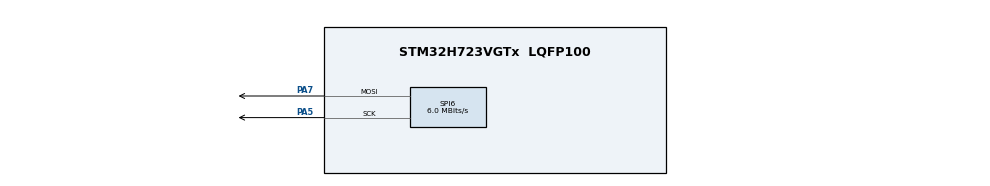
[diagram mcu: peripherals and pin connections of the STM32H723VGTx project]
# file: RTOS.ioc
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CORTEX_M7.default_mode_Activation=1
FREERTOS.Tasks01=defaultTask,0,128,StartDefaultTask,Default,NULL,Dynamic,NULL,NULL;Flash,0,128,StartFlashTask,Default,NULL,Dynamic,NULL,NULL;Breath,0,128,StartBreathTask,Default,NULL,Dynamic,NULL,NULL
Mcu.Family=STM32H7
Mcu.Name=STM32H723VGTx
Mcu.Package=LQFP100
NVIC.PriorityGroup=NVIC_PRIORITYGROUP_4
PA13(JTMS/SWDIO).Mode=Serial_Wire
PA13(JTMS/SWDIO).Signal=DEBUG_JTMS-SWDIO
PA14(JTCK/SWCLK).Mode=Serial_Wire
PA14(JTCK/SWCLK).Signal=DEBUG_JTCK-SWCLK
PA5.Mode=TX_Only_Simplex_Unidirect_Master
PA5.Signal=SPI6_SCK
PA7.Mode=TX_Only_Simplex_Unidirect_Master
PA7.Signal=SPI6_MOSI
PH0-OSC_IN.Mode=HSE-External-Oscillator
PH0-OSC_IN.Signal=RCC_OSC_IN
PH1-OSC_OUT.Mode=HSE-External-Oscillator
PH1-OSC_OUT.Signal=RCC_OSC_OUT
ProjectManager.HeapSize=0x200
ProjectManager.StackSize=0x400
ProjectManager.TargetToolchain=CMake
RCC.ADCFreq_Value=48375000
RCC.APB1Freq_Value=120000000
RCC.APB2Freq_Value=120000000
RCC.APB3Freq_Value=120000000
RCC.APB4Freq_Value=120000000
RCC.CortexFreq_Value=480000000
RCC.D1PPRE=RCC_APB3_DIV2
RCC.D2PPRE1=RCC_APB1_DIV2
RCC.D2PPRE2=RCC_APB2_DIV2
RCC.D3PPRE=RCC_APB4_DIV2
RCC.DIVM1=2
RCC.DIVN1=40
RCC.DIVP1=1
RCC.HCLKFreq_Value=240000000
RCC.HPRE=RCC_HCLK_DIV2
RCC.HSE_VALUE=24000000
RCC.PLLFRACN=0
RCC.PLLSourceVirtual=RCC_PLLSOURCE_HSE
RCC.SPI6CLockSelection=RCC_SPI6CLKSOURCE_HSE
RCC.SYSCLKFreq_VALUE=480000000
RCC.SYSCLKSource=RCC_SYSCLKSOURCE_PLLCLK
RCC.USBFreq_Value=240000000
SPI6.BaudRatePrescaler=SPI_BAUDRATEPRESCALER_4
SPI6.CLKPhase=SPI_PHASE_2EDGE
SPI6.CalculateBaudRate=6.0 MBits/s
SPI6.DataSize=SPI_DATASIZE_8BIT
SPI6.Direction=SPI_DIRECTION_2LINES_TXONLY
SPI6.Mode=SPI_MODE_MASTER
SPI6.VirtualType=VM_MASTER
VP_FREERTOS_VS_CMSIS_V1.Mode=CMSIS_V1
VP_MEMORYMAP_VS_MEMORYMAP.Mode=CurAppReg
board=custom

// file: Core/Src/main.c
/* USER CODE BEGIN Header */
/**
  ******************************************************************************
  * @file           : main.c
  * @brief          : Main program body
  ******************************************************************************
  * @attention
  *
  * Copyright (c) 2025 STMicroelectronics.
  * All rights reserved.
  *
  * This software is licensed under terms that can be found in the LICENSE file
  * in the root directory of this software component.
  * If no LICENSE file comes with this software, it is provided AS-IS.
  *
  ******************************************************************************
  */
/* USER CODE END Header */
#include "main.h"
#include "cmsis_os.h"
#include "memorymap.h"
#include "spi.h"
#include "gpio.h"

void SystemClock_Config(void);
static void MPU_Config(void);
void MX_FREERTOS_Init(void);

int main(void)
{

  /* MPU Configuration--------------------------------------------------------*/
  MPU_Config();

  /* MCU Configuration--------------------------------------------------------*/

  /* Reset of all peripherals, Initializes the Flash interface and the Systick. */
  HAL_Init();

  /* Configure the system clock */
  SystemClock_Config();

  /* Initialize all configured peripherals */
  MX_GPIO_Init();
  MX_SPI6_Init();

  /* Call init function for freertos objects (in cmsis_os2.c) */
  MX_FREERTOS_Init();

  /* Start scheduler */
  osKernelStart();

  /* We should never get here as control is now taken by the scheduler */

  /* Infinite loop */
  while (1)
  {

  }
}

void SystemClock_Config(void)
{
  RCC_OscInitTypeDef RCC_OscInitStruct = {0};
  RCC_ClkInitTypeDef RCC_ClkInitStruct = {0};

  /** Supply configuration update enable
  */
  HAL_PWREx_ConfigSupply(PWR_LDO_SUPPLY);

  /** Configure the main internal regulator output voltage
  */
  __HAL_PWR_VOLTAGESCALING_CONFIG(PWR_REGULATOR_VOLTAGE_SCALE0);

  while(!__HAL_PWR_GET_FLAG(PWR_FLAG_VOSRDY)) {}

  /** Initializes the RCC Oscillators according to the specified parameters
  * in the RCC_OscInitTypeDef structure.
  */
  RCC_OscInitStruct.OscillatorType = RCC_OSCILLATORTYPE_HSE;
  RCC_OscInitStruct.HSEState = RCC_HSE_ON;
  RCC_OscInitStruct.PLL.PLLState = RCC_PLL_ON;
  RCC_OscInitStruct.PLL.PLLSource = RCC_PLLSOURCE_HSE;
  RCC_OscInitStruct.PLL.PLLM = 2;
  RCC_OscInitStruct.PLL.PLLN = 40;
  RCC_OscInitStruct.PLL.PLLP = 1;
  RCC_OscInitStruct.PLL.PLLQ = 2;
  RCC_OscInitStruct.PLL.PLLR = 2;
  RCC_OscInitStruct.PLL.PLLRGE = RCC_PLL1VCIRANGE_3;
  RCC_OscInitStruct.PLL.PLLVCOSEL = RCC_PLL1VCOWIDE;
  RCC_OscInitStruct.PLL.PLLFRACN = 0;
  if (HAL_RCC_OscConfig(&RCC_OscInitStruct) != HAL_OK)
  {
    Error_Handler();
  }

  /** Initializes the CPU, AHB and APB buses clocks
  */
  RCC_ClkInitStruct.ClockType = RCC_CLOCKTYPE_HCLK|RCC_CLOCKTYPE_SYSCLK
                              |RCC_CLOCKTYPE_PCLK1|RCC_CLOCKTYPE_PCLK2
                              |RCC_CLOCKTYPE_D3PCLK1|RCC_CLOCKTYPE_D1PCLK1;
  RCC_ClkInitStruct.SYSCLKSource = RCC_SYSCLKSOURCE_PLLCLK;
  RCC_ClkInitStruct.SYSCLKDivider = RCC_SYSCLK_DIV1;
  RCC_ClkInitStruct.AHBCLKDivider = RCC_HCLK_DIV2;
  RCC_ClkInitStruct.APB3CLKDivider = RCC_APB3_DIV2;
  RCC_ClkInitStruct.APB1CLKDivider = RCC_APB1_DIV2;
  RCC_ClkInitStruct.APB2CLKDivider = RCC_APB2_DIV2;
  RCC_ClkInitStruct.APB4CLKDivider = RCC_APB4_DIV2;

  if (HAL_RCC_ClockConfig(&RCC_ClkInitStruct, FLASH_LATENCY_3) != HAL_OK)
  {
    Error_Handler();
  }
}

 /* MPU Configuration */

void MPU_Config(void)
{
  MPU_Region_InitTypeDef MPU_InitStruct = {0};

  /* Disables the MPU */
  HAL_MPU_Disable();

  /** Initializes and configures the Region and the memory to be protected
  */
  MPU_InitStruct.Enable = MPU_REGION_ENABLE;
  MPU_InitStruct.Number = MPU_REGION_NUMBER0;
  MPU_InitStruct.BaseAddress = 0x0;
  MPU_InitStruct.Size = MPU_REGION_SIZE_4GB;
  MPU_InitStruct.SubRegionDisable = 0x87;
  MPU_InitStruct.TypeExtField = MPU_TEX_LEVEL0;
  MPU_InitStruct.AccessPermission = MPU_REGION_NO_ACCESS;
  MPU_InitStruct.DisableExec = MPU_INSTRUCTION_ACCESS_DISABLE;
  MPU_InitStruct.IsShareable = MPU_ACCESS_SHAREABLE;
  MPU_InitStruct.IsCacheable = MPU_ACCESS_NOT_CACHEABLE;
  MPU_InitStruct.IsBufferable = MPU_ACCESS_NOT_BUFFERABLE;

  HAL_MPU_ConfigRegion(&MPU_InitStruct);
  /* Enables the MPU */
  HAL_MPU_Enable(MPU_PRIVILEGED_DEFAULT);

}

void Error_Handler(void)
{
  __disable_irq();
  while (1)
  {
  }
}

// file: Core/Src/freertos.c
/* USER CODE BEGIN Header */
/**
  ******************************************************************************
  * File Name          : freertos.c
  * Description        : Code for freertos applications
  ******************************************************************************
  * @attention
  *
  * Copyright (c) 2025 STMicroelectronics.
  * All rights reserved.
  *
  * This software is licensed under terms that can be found in the LICENSE file
  * in the root directory of this software component.
  * If no LICENSE file comes with this software, it is provided AS-IS.
  *
  ******************************************************************************
  */
/* USER CODE END Header */

#include "FreeRTOS.h"
#include "task.h"
#include "main.h"
#include "cmsis_os.h"
#include "WS2812.h"

/* USER CODE BEGIN Variables */

int r = 0;
int g = 0;
int b = 0;

float Sin_Sign;

/* USER CODE END Variables */
osThreadId defaultTaskHandle;
osThreadId FlashHandle;
osThreadId BreathHandle;

void StartDefaultTask(void const *argument);

void StartFlashTask(void const *argument);

void StartBreathTask(void const *argument);

void MX_FREERTOS_Init(void); /* (MISRA C 2004 rule 8.1) */

/* GetIdleTaskMemory prototype (linked to static allocation support) */
void vApplicationGetIdleTaskMemory(StaticTask_t **ppxIdleTaskTCBBuffer, StackType_t **ppxIdleTaskStackBuffer,
                                   uint32_t *pulIdleTaskStackSize);

/* USER CODE BEGIN GET_IDLE_TASK_MEMORY */
static StaticTask_t xIdleTaskTCBBuffer;
static StackType_t xIdleStack[configMINIMAL_STACK_SIZE];

void vApplicationGetIdleTaskMemory(StaticTask_t **ppxIdleTaskTCBBuffer, StackType_t **ppxIdleTaskStackBuffer,
                                   uint32_t *pulIdleTaskStackSize) {
    *ppxIdleTaskTCBBuffer = &xIdleTaskTCBBuffer;
    *ppxIdleTaskStackBuffer = &xIdleStack[0];
    *pulIdleTaskStackSize = configMINIMAL_STACK_SIZE;
    /* place for user code */
}
/* USER CODE END GET_IDLE_TASK_MEMORY */

void MX_FREERTOS_Init(void) {

    /* Create the thread(s) */
    /* definition and creation of defaultTask */
    osThreadDef(defaultTask, StartDefaultTask, osPriorityNormal, 0, 128);
    defaultTaskHandle = osThreadCreate(osThread(defaultTask), NULL);

    /* definition and creation of Flash */
    osThreadDef(Flash, StartFlashTask, osPriorityNormal, 0, 128);
    FlashHandle = osThreadCreate(osThread(Flash), NULL);

    /* definition and creation of Breath */
    osThreadDef(Breath, StartBreathTask, osPriorityNormal, 0, 128);
    BreathHandle = osThreadCreate(osThread(Breath), NULL);

}

void StartDefaultTask(void const *argument) {
    for (;;) {
        osDelay(1);
    }
}

void StartFlashTask(void const *argument) {
    /* USER CODE BEGIN StartFlashTask */

    static int i = 0;

    /* Infinite loop */
    for (;;) {

        if (i % 2 == 0) {
            r = 10;
        } else if (i % 2 == 1) {
            r = 0;
        }

        i++;

        WS2812_Ctrl(r, g, b);
        osDelay(500); // 500ms
    }
    /* USER CODE END StartFlashTask */
}

void StartBreathTask(void const *argument) {
    /* USER CODE BEGIN StartBreathTask */

    static float i = 0.0f;

    /* Infinite loop */
    for (;;) {

        Sin_Sign = sin(i);

        if (Sin_Sign < 0) {
            Sin_Sign = 0;
        }

        i += 0.01f;

        if (i > 360.0f) {
            i = 0.0f;
        }

        g = 10 * Sin_Sign;

        WS2812_Ctrl(r, g, b);

        osDelay(5);
    }
    /* USER CODE END StartBreathTask */
}
